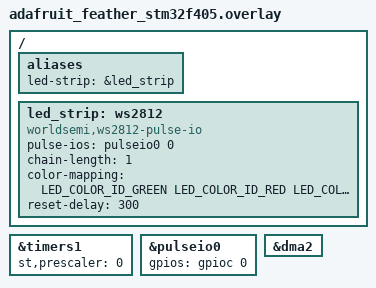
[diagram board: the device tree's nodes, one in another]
/*
 * Copyright (c) 2026 Dent IoT
 *
 * SPDX-License-Identifier: Apache-2.0
 *
 * Drives the on-board WS2812 (NeoPixel) on the Adafruit Feather STM32F405
 * Express. The NeoPixel data line is on PC0, which has no usable alternate
 * functions, so it is driven by the STM32 pulse_io backend using a timer
 * update event triggering DMA writes to GPIOC->BSRR. No pin AF is needed.
 *
 * Timer: TIM1 (APB2, 168 MHz). TIM1_UP routes to DMA2 stream5/channel6.
 * DMA2 (unlike DMA1 on F405/407) can reach the GPIO AHB1 port.
 *
 * Copy this overlay alongside your build (e.g. into a sample's boards/
 * directory, or pass with --overlay) and build for
 * adafruit_feather_stm32f405.
 */

#include <zephyr/dt-bindings/led/led.h>
#include <zephyr/dt-bindings/dma/stm32_dma.h>

&timers1 {
	st,prescaler = <0>;
	status = "okay";
};

// We need pulseio to drive the ws2812
// because the dataline is not attached to
// any useful peripheral.
&pulseio0 {
	status = "okay";
	/* PC0 = on-board NeoPixel data line */
	gpios = <&gpioc 0 0>;
};

/ {
	aliases {
		led-strip = &led_strip;
	};

	led_strip: ws2812 {
		compatible = "worldsemi,ws2812-pulse-io";
		pulse-ios = <&pulseio0 0>;
		chain-length = <1>;
		color-mapping = <LED_COLOR_ID_GREEN
				 LED_COLOR_ID_RED
				 LED_COLOR_ID_BLUE>;
		reset-delay = <300>;
	};
};

/* Enable DMA2 (only DMA2 can reach GPIO on F405/407). */
&dma2 {
	status = "okay";
};
